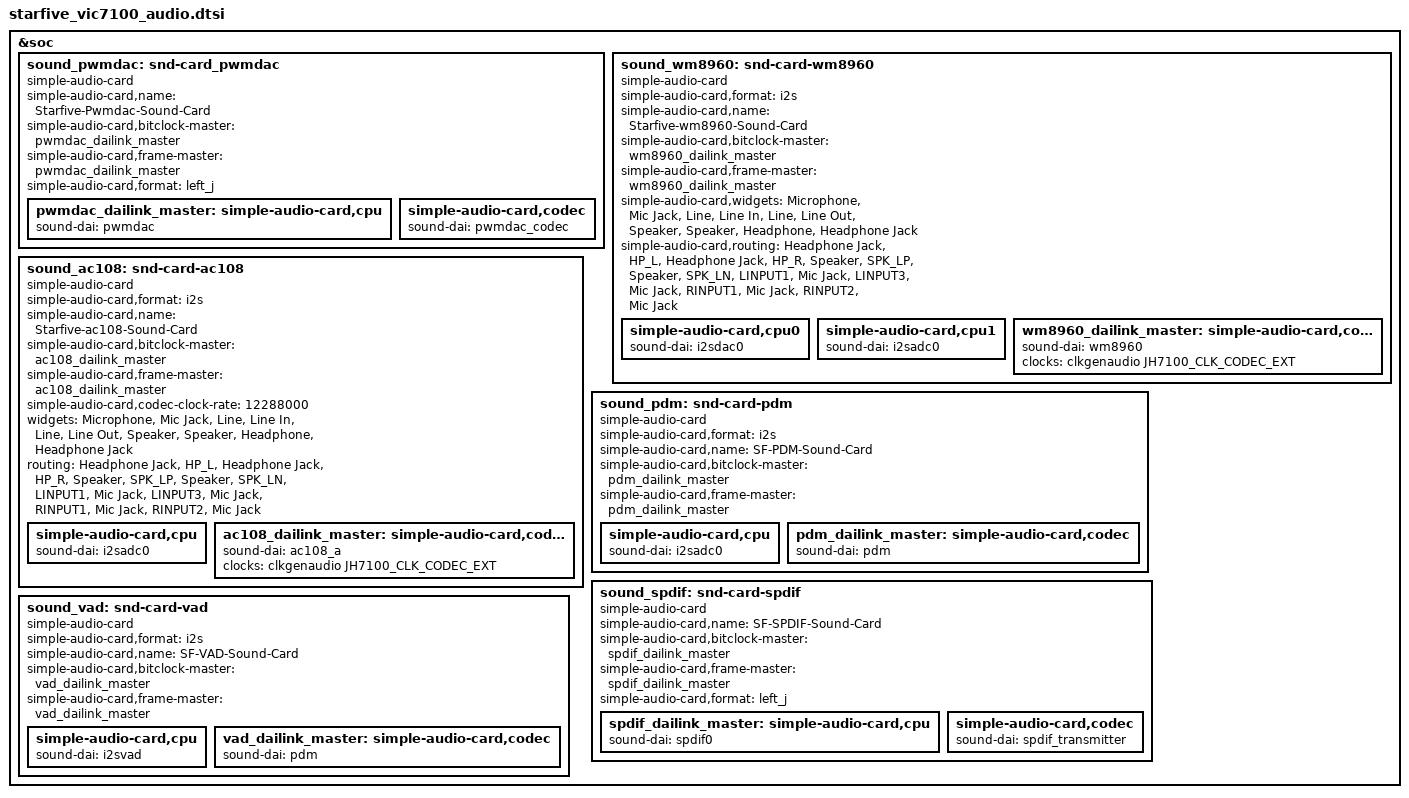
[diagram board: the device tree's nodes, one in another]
&soc{
	sound_pwmdac:snd-card_pwmdac{
			compatible = "simple-audio-card";
			simple-audio-card,name = "Starfive-Pwmdac-Sound-Card";
			simple-audio-card,bitclock-master = <&pwmdac_dailink_master>;
			simple-audio-card,frame-master = <&pwmdac_dailink_master>;
			simple-audio-card,format = "left_j";
			pwmdac_dailink_master:simple-audio-card,cpu {
				sound-dai = <&pwmdac>;
			};

			simple-audio-card,codec {
				sound-dai = <&pwmdac_codec>;
			};
		};

	sound_wm8960:snd-card-wm8960{
			compatible = "simple-audio-card";
			simple-audio-card,format = "i2s";
			simple-audio-card,name = "Starfive-wm8960-Sound-Card"; 
			simple-audio-card,bitclock-master = <&wm8960_dailink_master>;
			simple-audio-card,frame-master = <&wm8960_dailink_master>;

			status = "okay";
			simple-audio-card,widgets =
					"Microphone", "Mic Jack",
					"Line", "Line In",
					"Line", "Line Out",
					"Speaker", "Speaker",
					"Headphone", "Headphone Jack";
			simple-audio-card,routing =
					"Headphone Jack", "HP_L",
					"Headphone Jack", "HP_R",
					"Speaker", "SPK_LP",
					"Speaker", "SPK_LN",
					"LINPUT1", "Mic Jack",
					"LINPUT3", "Mic Jack",
					"RINPUT1", "Mic Jack",
					"RINPUT2", "Mic Jack";
			simple-audio-card,cpu0 {
					sound-dai = <&i2sdac0>;
				};
			simple-audio-card,cpu1 {
					sound-dai = <&i2sadc0>;
				};

			wm8960_dailink_master:simple-audio-card,codec {
				sound-dai = <&wm8960>;
				clocks = <&clkgenaudio JH7100_CLK_CODEC_EXT>;
				clock-names = "mclk";
			};
	};
	
	sound_ac108:snd-card-ac108{
		compatible = "simple-audio-card";
		simple-audio-card,format = "i2s";
		simple-audio-card,name = "Starfive-ac108-Sound-Card"; 
		simple-audio-card,bitclock-master = <&ac108_dailink_master>;
		simple-audio-card,frame-master = <&ac108_dailink_master>;
		simple-audio-card,codec-clock-rate = <12288000>;
		status = "okay";
		widgets =
				"Microphone", "Mic Jack",
				"Line", "Line In",
				"Line", "Line Out",
				"Speaker", "Speaker",
				"Headphone", "Headphone Jack";
		routing =
				"Headphone Jack", "HP_L",
				"Headphone Jack", "HP_R",
				"Speaker", "SPK_LP",
				"Speaker", "SPK_LN",
				"LINPUT1", "Mic Jack",
				"LINPUT3", "Mic Jack",
				"RINPUT1", "Mic Jack",
				"RINPUT2", "Mic Jack";
		simple-audio-card,cpu {
			sound-dai = <&i2sadc0>;
		};
		
		ac108_dailink_master:simple-audio-card,codec {
			sound-dai = <&ac108_a>;
			clocks = <&clkgenaudio JH7100_CLK_CODEC_EXT>;
			clock-names = "mclk";
		};
	};
	
	sound_pdm:snd-card-pdm{
		compatible = "simple-audio-card";
		simple-audio-card,format = "i2s";
		simple-audio-card,name = "SF-PDM-Sound-Card";
		simple-audio-card,bitclock-master = <&pdm_dailink_master>;
		simple-audio-card,frame-master = <&pdm_dailink_master>;
		status = "okay";
		simple-audio-card,cpu {
			sound-dai = <&i2sadc0>;
		};
		
		pdm_dailink_master:simple-audio-card,codec {
			sound-dai = <&pdm>;
		};
	};
	
	sound_spdif:snd-card-spdif{
		compatible = "simple-audio-card";
		simple-audio-card,name = "SF-SPDIF-Sound-Card";
		simple-audio-card,bitclock-master = <&spdif_dailink_master>;
		simple-audio-card,frame-master = <&spdif_dailink_master>;
		simple-audio-card,format = "left_j";
		spdif_dailink_master:simple-audio-card,cpu {
			sound-dai = <&spdif0>;
		};

		simple-audio-card,codec {
			sound-dai = <&spdif_transmitter>;
		};
	};
	
	sound_vad:snd-card-vad{
		compatible = "simple-audio-card";
		simple-audio-card,format = "i2s";
		simple-audio-card,name = "SF-VAD-Sound-Card";
		simple-audio-card,bitclock-master = <&vad_dailink_master>;
		simple-audio-card,frame-master = <&vad_dailink_master>;
		status = "okay";
		simple-audio-card,cpu {
			sound-dai = <&i2svad>;
		};
		
		vad_dailink_master:simple-audio-card,codec {
			sound-dai = <&pdm>;
		};
	};
};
